AUTOSAR XML (schema 4-2-2)
package /EB/SoftwareComponents
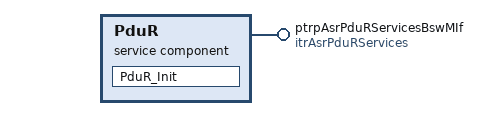
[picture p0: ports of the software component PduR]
  service sw component type PduR: category=ASR_Interfaces
    provide port ptrpAsrPduRServicesBswMIf: provided-interface=itrAsrPduRServices
    behavior PduR_IB: handle-termination-and-restart=NO-SUPPORT
      runnable PduR_Init
package /EB/TriggerInterfaces
  trigger interface itrAsrPduRServices
    trigger PduR_Init: trigger-period={cse-code=1000, cse-code-factor=0}
